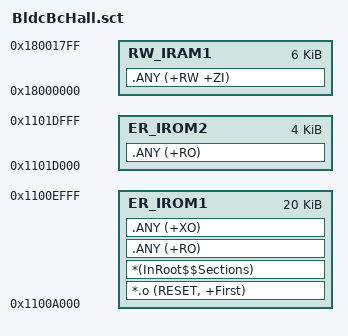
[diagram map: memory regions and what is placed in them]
; *************************************************************
; *** Scatter-Loading Description File generated by uVision ***
; *************************************************************

LR_IROM1 0x1100A000 0x00005000  {    ; load region size_region
  ER_IROM1 0x1100A000 0x00005000  {  ; load address = execution address
   *.o (RESET, +First)
   *(InRoot$$Sections)
   .ANY (+RO)
   .ANY (+XO)
  }
  RW_IRAM1 0x18000000 0x00001800  {  ; RW data
   .ANY (+RW +ZI)
  }
}

LR_IROM2 0x1101D000 0x00001000  {
  ER_IROM2 0x1101D000 0x00001000  {  ; load address = execution address
   .ANY (+RO)
  }
}
